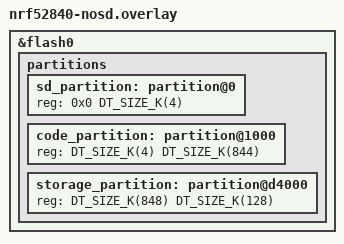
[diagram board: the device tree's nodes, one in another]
/*
 * Copyright (c) 2024 The ZMK Contributors
 *
 * SPDX-License-Identifier: MIT
 */

/delete-node/ &sd_partition;
/delete-node/ &code_partition;
/delete-node/ &storage_partition;

&flash0 {
    partitions {
        sd_partition: partition@0 {
            reg = <0x0 DT_SIZE_K(4)>;
        };

        code_partition: partition@1000 {
            reg = <DT_SIZE_K(4) DT_SIZE_K(844)>;
        };

        /*
         * The flash starting at 0x000d4000 and ending at
         * 0x000f3fff is reserved for use by the application.
         */

        /*
         * Storage partition will be used by FCB/LittleFS/NVS
         * if enabled.
         */
        storage_partition: partition@d4000 {
            reg = <DT_SIZE_K(848) DT_SIZE_K(128)>;
        };
    };
};
